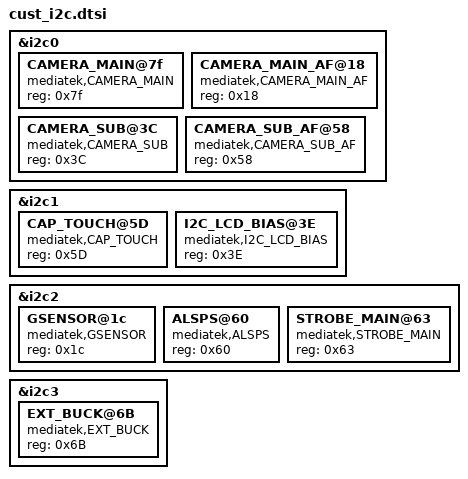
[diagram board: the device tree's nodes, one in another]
/*
 * Generated by MTK SP DrvGen Version 03.13.6 for MT6735M. Copyright MediaTek Inc. (C) 2013.
 * Tue Jan 10 00:14:52 2017
 * Do Not Modify the File.
 */

/*************************
 * I2C DTSI File
*************************/

&i2c0 {
	CAMERA_MAIN@7f {
		compatible = "mediatek,CAMERA_MAIN";
		reg = <0x7f>;
	};

	CAMERA_MAIN_AF@18 {
		compatible = "mediatek,CAMERA_MAIN_AF";
		reg = <0x18>;
	};

	CAMERA_SUB@3C {
		compatible = "mediatek,CAMERA_SUB";
		reg = <0x3C>;
	};

	CAMERA_SUB_AF@58 {
		compatible = "mediatek,CAMERA_SUB_AF";
		reg = <0x58>;
	};

};

&i2c1 {
	CAP_TOUCH@5D {
		compatible = "mediatek,CAP_TOUCH";
		reg = <0x5D>;
	};

	I2C_LCD_BIAS@3E {
		compatible = "mediatek,I2C_LCD_BIAS";
		reg = <0x3E>;
	};

};

&i2c2 {
	GSENSOR@1c {
		compatible = "mediatek,GSENSOR";
		reg = <0x1c>;
	};

	ALSPS@60 {
		compatible = "mediatek,ALSPS";
		reg = <0x60>;
	};

	STROBE_MAIN@63 {
		compatible = "mediatek,STROBE_MAIN";
		reg = <0x63>;
	};

};

&i2c3 {
	EXT_BUCK@6B {
		compatible = "mediatek,EXT_BUCK";
		reg = <0x6B>;
	};

};

